AUTOSAR XML (schema 00044)
package /ComponentTypes
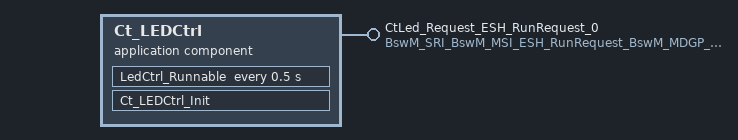
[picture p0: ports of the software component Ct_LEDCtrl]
  application sw component type Ct_LEDCtrl
    provide port CtLed_Request_ESH_RunRequest_0: nonqueued-sender-com-spec=requestedMode, provided-interface=BswM_SRI_BswM_MSI_ESH_RunRequest_BswM_MDGP_ESH_RunRequest
    behavior Ct_LEDCtrl_InternalBehavior
      timing event TMT_LedCtrl_Runnable: start-on-event=LedCtrl_Runnable, period=0.5
      init event Ct_LEDCtrl_InitEvent: start-on-event=Ct_LEDCtrl_Init
      runnable LedCtrl_Runnable
        data-send-points:
          access SEND_CtLed_Request_ESH_RunRequest_0_requestedMode: accessed-variable=CtLed_Request_ESH_RunRequest_0.requestedMode
      runnable Ct_LEDCtrl_Init
  swc implementation Ct_LEDCtrl_Implementation: behavior=Ct_LEDCtrl_InternalBehavior
